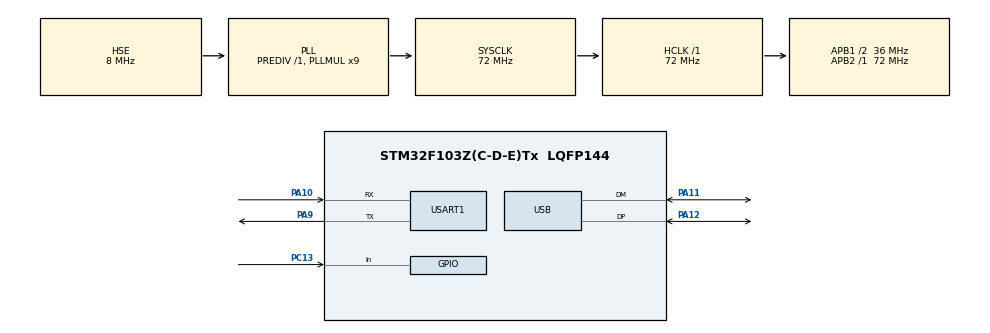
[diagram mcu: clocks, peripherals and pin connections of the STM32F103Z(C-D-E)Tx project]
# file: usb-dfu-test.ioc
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Mcu.Family=STM32F1
Mcu.Name=STM32F103Z(C-D-E)Tx
Mcu.Package=LQFP144
NVIC.PriorityGroup=NVIC_PRIORITYGROUP_4
NVIC.USB_LP_CAN1_RX0_IRQn=true\:0\:0\:false\:false\:true\:false\:true\:true
OSC_IN.Mode=HSE-External-Oscillator
OSC_IN.Signal=RCC_OSC_IN
OSC_OUT.Mode=HSE-External-Oscillator
OSC_OUT.Signal=RCC_OSC_OUT
PA10.Mode=Asynchronous
PA10.Signal=USART1_RX
PA11.Mode=Device
PA11.Signal=USB_DM
PA12.Mode=Device
PA12.Signal=USB_DP
PA13.Mode=Serial_Wire
PA13.Signal=SYS_JTMS-SWDIO
PA14.Mode=Serial_Wire
PA14.Signal=SYS_JTCK-SWCLK
PA9.Mode=Asynchronous
PA9.Signal=USART1_TX
PC13-TAMPER-RTC.Signal=GPIO_Input
ProjectManager.HeapSize=0x200
ProjectManager.StackSize=0x400
ProjectManager.TargetToolchain=STM32CubeIDE
RCC.AHBFreq_Value=72000000
RCC.APB1CLKDivider=RCC_HCLK_DIV2
RCC.APB1Freq_Value=36000000
RCC.APB1TimFreq_Value=72000000
RCC.APB2Freq_Value=72000000
RCC.APB2TimFreq_Value=72000000
RCC.HCLKFreq_Value=72000000
RCC.PLLMUL=RCC_PLL_MUL9
RCC.SYSCLKFreq_VALUE=72000000
RCC.SYSCLKSource=RCC_SYSCLKSOURCE_PLLCLK
RCC.USBFreq_Value=48000000
RCC.USBPrescaler=RCC_USBCLKSOURCE_PLL_DIV1_5
USART1.VirtualMode=VM_ASYNC
USB_DEVICE.CLASS_NAME_FS=DFU
USB_DEVICE.VirtualMode=Dfu
USB_DEVICE.VirtualModeFS=Dfu_FS
VP_USB_DEVICE_VS_USB_DEVICE_DFU_FS.Mode=DFU_FS
board=custom

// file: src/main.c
/* USER CODE BEGIN Header */
/**
  ******************************************************************************
  * @file           : main.c
  * @brief          : Main program body
  ******************************************************************************
  * @attention
  *
  * Copyright (c) 2024 STMicroelectronics.
  * All rights reserved.
  *
  * This software is licensed under terms that can be found in the LICENSE file
  * in the root directory of this software component.
  * If no LICENSE file comes with this software, it is provided AS-IS.
  *
  ******************************************************************************
  */
/* USER CODE END Header */
#include "main.h"
#include "usart.h"
#include "usb_device.h"
#include "gpio.h"
#include "rtc_bkp.h"

/* USER CODE BEGIN PM */
//复位后拉低usb引脚让电脑重新枚举，这样不需要断电。
void soft_reconnect_usb(){
    GPIO_InitTypeDef GPIO_InitStruct = {0};
    __HAL_RCC_GPIOA_CLK_ENABLE();
  HAL_GPIO_WritePin(GPIOA, GPIO_PIN_11|GPIO_PIN_12, GPIO_PIN_RESET);

  /*Configure GPIO pin : PG14 */
  GPIO_InitStruct.Pin = GPIO_PIN_11|GPIO_PIN_12;
  GPIO_InitStruct.Mode = GPIO_MODE_OUTPUT_PP;
  GPIO_InitStruct.Pull = GPIO_PULLDOWN;
  GPIO_InitStruct.Speed = GPIO_SPEED_FREQ_LOW;
  HAL_GPIO_Init(GPIOA, &GPIO_InitStruct);
  HAL_Delay(200);
}
/* USER CODE END PM */

void SystemClock_Config(void);
#define APPLICATION_ADDRESS_START      USBD_DFU_APP_DEFAULT_ADD

typedef void (*pFunction)(void) ;//__attribute__((noreturn));
pFunction JumpToApplication;
uint32_t JumpAddresss;
void jump_to_APP(void)
{
   //printf("Jump to APP1\r\n");
	if (((*(__IO uint32_t*)APPLICATION_ADDRESS_START) & 0x2FFE0000 ) == 0x20000000)   //这里之后研究下为啥，貌似固件开头是0x20010000
	{
    //__disable_irq();
		JumpAddresss = *(__IO uint32_t*)(APPLICATION_ADDRESS_START+4);
   // printf("add %p\r\n",JumpAddresss);
		JumpToApplication = (pFunction)JumpAddresss;
		__set_MSP(*(__IO uint32_t*)APPLICATION_ADDRESS_START);
		JumpToApplication();
	}
}
/* USER CODE BEGIN 0 */
uint32_t magic_value=0;
/* USER CODE END 0 */

int main(void)
{

  /* MCU Configuration--------------------------------------------------------*/

  /* Reset of all peripherals, Initializes the Flash interface and the Systick. */
  HAL_Init();

  /* Configure the system clock */
  SystemClock_Config();
  soft_reconnect_usb();
  MX_GPIO_Init();
  MX_USART1_UART_Init();
   // uint8_t sftrst= __HAL_RCC_GET_FLAG(RCC_FLAG_SFTRST)>>RCC_CSR_SFTRSTF_Pos;
    uint8_t sftrst= __HAL_RCC_GET_FLAG(RCC_FLAG_SFTRST)&&RCC_CSR_SFTRSTF_Msk;
   __HAL_RCC_CLEAR_RESET_FLAGS();
  if(sftrst){
    HAL_PWR_EnableBkUpAccess();
    __HAL_RCC_BKP_CLK_ENABLE() ;
    magic_value|=HAL_RTCEx_BKUPRead(&hrtc,RTC_BKP_DR1);
    magic_value|=HAL_RTCEx_BKUPRead(&hrtc,RTC_BKP_DR2)<<16;
    if(magic_value==MAGIC_VALUE)
    {
      uint8_t tmp=HAL_RTCEx_BKUPRead(&hrtc,RTC_BKP_DR3);
      HAL_RTCEx_BKUPWrite(&hrtc,RTC_BKP_DR3,0);
      if(tmp!=RESET_TO_DFU){
          printf("jump to APP\n");
          jump_to_APP();
      }
    }
  }else if(HAL_GPIO_ReadPin(GPIOC,GPIO_PIN_13))
  {
    HAL_Delay(10);
    if(HAL_GPIO_ReadPin(GPIOC,GPIO_PIN_13))
    {
      printf("jump to APP\n");
      jump_to_APP();
    }
  }

  /* Initialize all configured peripherals */

  MX_USB_DEVICE_Init();
  printf(" dfu upgrade\n\r");

  /* Infinite loop */
  while (1)
  {
    HAL_GPIO_TogglePin(GPIOG,GPIO_PIN_14);
    HAL_Delay(100);
  }
}

void SystemClock_Config(void)
{
  RCC_OscInitTypeDef RCC_OscInitStruct = {0};
  RCC_ClkInitTypeDef RCC_ClkInitStruct = {0};
  RCC_PeriphCLKInitTypeDef PeriphClkInit = {0};

  /** Initializes the RCC Oscillators according to the specified parameters
  * in the RCC_OscInitTypeDef structure.
  */
  RCC_OscInitStruct.OscillatorType = RCC_OSCILLATORTYPE_HSE;
  RCC_OscInitStruct.HSEState = RCC_HSE_ON;
  RCC_OscInitStruct.HSEPredivValue = RCC_HSE_PREDIV_DIV1;
  RCC_OscInitStruct.HSIState = RCC_HSI_ON;
  RCC_OscInitStruct.PLL.PLLState = RCC_PLL_ON;
  RCC_OscInitStruct.PLL.PLLSource = RCC_PLLSOURCE_HSE;
  RCC_OscInitStruct.PLL.PLLMUL = RCC_PLL_MUL9;
  if (HAL_RCC_OscConfig(&RCC_OscInitStruct) != HAL_OK)
  {
    Error_Handler();
  }

  /** Initializes the CPU, AHB and APB buses clocks
  */
  RCC_ClkInitStruct.ClockType = RCC_CLOCKTYPE_HCLK|RCC_CLOCKTYPE_SYSCLK
                              |RCC_CLOCKTYPE_PCLK1|RCC_CLOCKTYPE_PCLK2;
  RCC_ClkInitStruct.SYSCLKSource = RCC_SYSCLKSOURCE_PLLCLK;
  RCC_ClkInitStruct.AHBCLKDivider = RCC_SYSCLK_DIV1;
  RCC_ClkInitStruct.APB1CLKDivider = RCC_HCLK_DIV2;
  RCC_ClkInitStruct.APB2CLKDivider = RCC_HCLK_DIV1;

  if (HAL_RCC_ClockConfig(&RCC_ClkInitStruct, FLASH_LATENCY_2) != HAL_OK)
  {
    Error_Handler();
  }
  PeriphClkInit.PeriphClockSelection = RCC_PERIPHCLK_USB;
  PeriphClkInit.UsbClockSelection = RCC_USBCLKSOURCE_PLL_DIV1_5;
  if (HAL_RCCEx_PeriphCLKConfig(&PeriphClkInit) != HAL_OK)
  {
    Error_Handler();
  }
}

void Error_Handler(void)
{
  __disable_irq();
  while (1)
  {
  }
}
